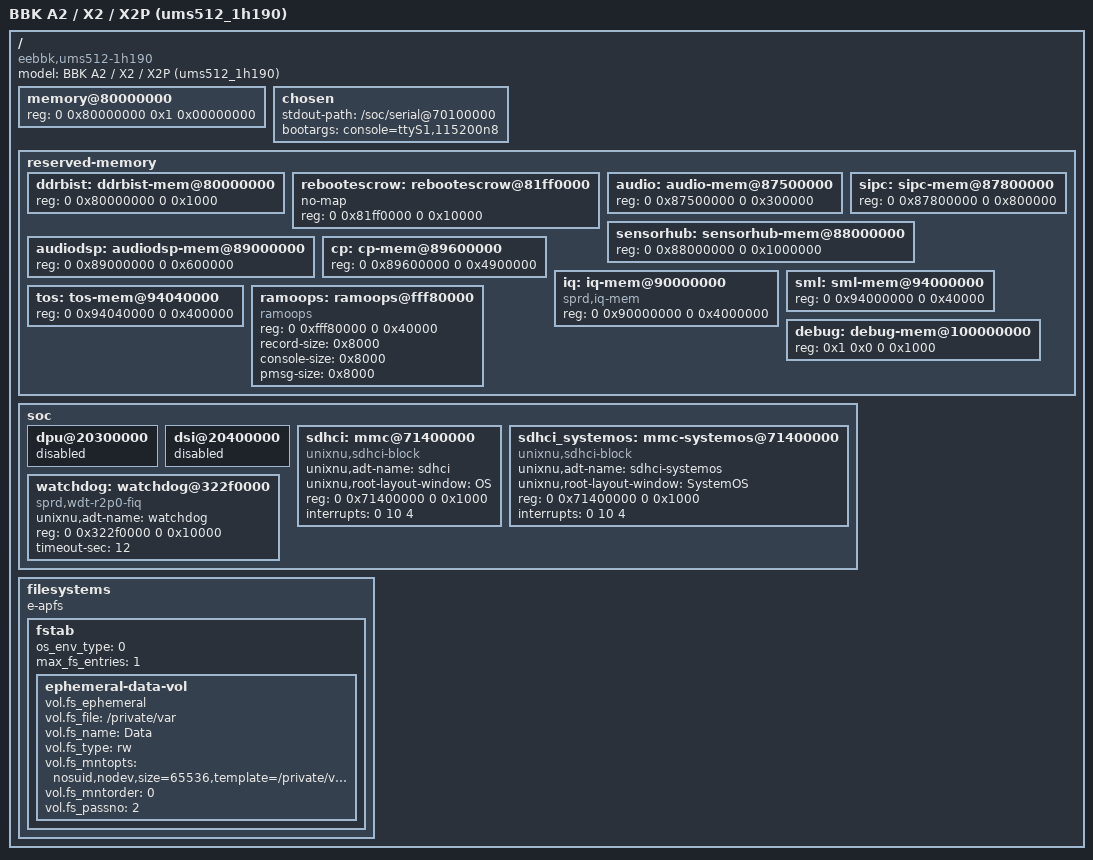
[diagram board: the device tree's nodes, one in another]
/*
 * BBK / EEBBK A2, X2, X2P tablet device tree.
 *
 * Board: ums512_1h190 (TWRP device tree: hxzbaka/twrp_device_eebbk_ums512_1h190-A2)
 * SoC:   Unisoc UMS512 / SharkL5Pro (T610 family), 2 GiB DRAM at 0x80000000
 *
 * All values below come from the vendor boot.bin appended DTB
 * (analysis/extracted/boot/boot-dtb.dtb, decompiled to boot-dtb.dts).
 */

/dts-v1/;
/include/ "ums512.dtsi"

/ {
	model = "BBK A2 / X2 / X2P (ums512_1h190)";
	compatible = "eebbk,ums512-1h190", "sprd,ums512";

	/* 1 GiB: U-Boot reports "DRAM: 1 GiB" (two 512 MiB banks) and the UEFI
 * MemoryMapLib now describes the full runtime-FDT span 0x80000000..0x17FFFF000.
 * says 2 GiB, which does not match this board. */
	memory@80000000 {
		device_type = "memory";
		reg = <0 0x80000000 0x1 0x00000000>;   /* 4 GiB: size hi/lo cells */
	};

	chosen {
		stdout-path = "/soc/serial@70100000";
		bootargs = "console=ttyS1,115200n8";
	};

	/*
	 * Reserved regions from the vendor FDT.  The UEFI MemoryMapLib must
	 * describe these as reserved/ACPI-reclaim-free so EDK2 never allocates
	 * on top of the TEE, modem, DSP or ramoops regions.
	 */
	reserved-memory {
		#address-cells = <2>;
		#size-cells = <2>;
		ranges;

		ddrbist: ddrbist-mem@80000000 {
			reg = <0 0x80000000 0 0x1000>;
		};
		rebootescrow: rebootescrow@81ff0000 {
			no-map;
			reg = <0 0x81ff0000 0 0x10000>;
		};
		audio: audio-mem@87500000 {
			reg = <0 0x87500000 0 0x300000>;
		};
		sipc: sipc-mem@87800000 {
			reg = <0 0x87800000 0 0x800000>;
		};
		sensorhub: sensorhub-mem@88000000 {
			reg = <0 0x88000000 0 0x1000000>;
		};
		audiodsp: audiodsp-mem@89000000 {
			reg = <0 0x89000000 0 0x600000>;
		};
		cp: cp-mem@89600000 {
			reg = <0 0x89600000 0 0x4900000>;
		};
		iq: iq-mem@90000000 {
			compatible = "sprd,iq-mem";
			reg = <0 0x90000000 0 0x4000000>;
		};
		sml: sml-mem@94000000 {
			reg = <0 0x94000000 0 0x40000>;
		};
		tos: tos-mem@94040000 {
			reg = <0 0x94040000 0 0x400000>;
		};
		ramoops: ramoops@fff80000 {
			compatible = "ramoops";
			reg = <0 0xfff80000 0 0x40000>;
			record-size = <0x8000>;
			console-size = <0x8000>;
			pmsg-size = <0x8000>;
		};
		debug: debug-mem@100000000 {
			reg = <0x1 0x0 0 0x1000>;
		};
	};

	/* Display: vendor DPU/DSI + 1200x1920 portrait MIPI panel, Goodix touch.
	 * Not exported to the ADT yet (status disabled) - first bring-up relies on
	 * the framebuffer left by the stock bootloader. */
	soc {
		dpu@20300000 {
			status = "disabled";
		};
		dsi@20400000 {
			status = "disabled";
		};

		/* SDHCR11 SDHCI/eMMC host.  cboot leaves the controller initialised
		 * (clock control 0x0207, host control 0x20, host control 2 0x3000,
		 * vendor clock register 0x204 = 0x30303060) and the capabilities
		 * register reports a zero base clock, so the XNU driver only inherits
		 * that state and uses the vendor command path to read the GPT; see
		 * drivers/SdhciBlock.  GIC SPI 10, level high (#interrupt-cells = 3 of
		 * the intc node); the driver polls 0x30 and never enables the line.
		 * unixnu,sdhci-block is the IONameMatch of the NativeSdhciBlock
		 * personality, sprd,sdhc-r11p1 is the stock kernel's compatible. */
		sdhci: mmc@71400000 {
			compatible = "unixnu,sdhci-block", "sprd,sdhc-r11p1";
			unixnu,adt-name = "sdhci";
			/* SHNGROOT root-layout window this instance publishes. */
			unixnu,root-layout-window = "OS";
			reg = <0 0x71400000 0 0x1000>;
			interrupts = <0 10 4>;
			status = "okay";
		};

		/* Second instance of the same SDHCR11 controller: the SystemOS window
		 * carries the dyld shared cache and the SystemOS volume that the
		 * offline-owner cache mount binds at /private/preboot.  Both instances
		 * map the same registers and serialise their polled commands with a
		 * global lock (NativeSdhciBlock::controllerLock). */
		sdhci_systemos: mmc-systemos@71400000 {
			compatible = "unixnu,sdhci-block", "sprd,sdhc-r11p1";
			unixnu,adt-name = "sdhci-systemos";
			unixnu,root-layout-window = "SystemOS";
			reg = <0 0x71400000 0 0x1000>;
			interrupts = <0 10 4>;
			status = "okay";
		};

		/* Unisoc UMS512 watchdog.  This is a real platform node, not an
		 * Apple wdt,s5l8960x alias: NativeSprdWatchdog publishes the
		 * IOWatchdog service from the sprd,wdt-r2p0-fiq compatible.  The
		 * clock provider phandles from the original BSP tree are not
		 * present in this reduced ADT, so the driver uses the known
		 * enable/rtc_enable clock IDs directly. */
		watchdog: watchdog@322f0000 {
			compatible = "sprd,wdt-r2p0-fiq";
			unixnu,adt-name = "watchdog";
			reg = <0 0x322f0000 0 0x10000>;
			timeout-sec = <12>;
			clock-names = "enable", "rtc_enable";
			status = "okay";
		};
	};

	/*
	 * Apple's mount reads IODeviceTree:/filesystems/fstab for the user-space
	 * mount table.  The ramdisk branch (vol.fs_ephemeral) copies the template
	 * directory into a tmpfs, and parses size= from vol.fs_mntopts in units of
	 * 512-byte blocks: 32 MiB / 512 = 65536 = 0x10000.
	 */
	filesystems {
		e-apfs;

		fstab {
			/*
			 * The offline Data seed lives in its own RAM APFS container, while
			 * Apple's get_data_volume() only searches the boot container for
			 * APFS_VOL_ROLE_DATA.  Keep the non-main environment so that lookup
			 * is a warning instead of the phase-2 "missing data volume" exit;
			 * the ephemeral entry below still mounts the seed template as tmpfs.
			 */
			os_env_type = <0>;
			max_fs_entries = <1>;

			ephemeral-data-vol {
				vol.fs_ephemeral;
				vol.fs_file = "/private/var";
				vol.fs_name = "Data";
				vol.fs_type = "rw";
				vol.fs_mntopts = "nosuid,nodev,size=65536,template=/private/var/";
				vol.fs_mntorder = <0>;
				vol.fs_passno = <2>;
			};
		};
	};

};
